# RTL8195AM register map
Vendor: Realtek; Series: Ameba IOT; File version: 1.2
SINGLE-CHIP 802.11b/g/n 1T1R WLAN SoC
CPU: CM3 r2p0, little endian, MPU, no FPU, vendor SysTick, 4 interrupt priority bits
Registers are 32-bit, read-write, reset 0x0 unless marked. A register's access mark holds for its fields unless they carry their own. Offsets are from the block's base; lines under a group give offsets from that group; [hi:lo] are bit positions; {n}, {i} and the like mark numbered series; 'fields as' and 'values as' point back to an identical list; <NAME> marks a mode.

## Memory map
0x40000000 SYSCON
0x40001000 GPIO
0x40002000 Timer
0x40003000 LOG_UART
0x40006000 SPI_flash_controller
0x40040000 UART_0
0x40042000 SSI0
0x40042400 SSI1
0x40042800 SSI2

## SYSCON
Base 0x40000000
0x00 PWR_CTRL 16-bit
0x02 ISO_CTRL 16-bit
0x08 FUNC_EN 4096-bit (reset mask 0xFFFFFFFF)
0x10 CLK_CTRL0 4096-bit (reset mask 0xFFFFFFFF)
0x14 CLK_CTRL1 4096-bit (reset mask 0xFFFFFFFF)
{0x20+4i} EFUSE_SYSCFG{i} 4096-bit (reset mask 0xFFFFFFFF) (i=0..7)
0x40 REGU_CTRL0 4096-bit (reset mask 0xFFFFFFFF)
0x48 SWR_CTRL0 4096-bit (reset mask 0xFFFFFFFF)
0x4C SWR_CTRL1 4096-bit (reset mask 0xFFFFFFFF)
0x60 XTAL_CTRL0 4096-bit (reset mask 0xFFFFFFFF)
0x64 XTAL_CTRL1 4096-bit (reset mask 0xFFFFFFFF)
{0x70+4i} SYSPLL_CTRL{i} 4096-bit (reset mask 0xFFFFFFFF) (i=0..2)
0x90 ANA_TIM_CTRL 4096-bit (reset mask 0xFFFFFFFF)
0x94 DSLP_TIM_CTRL 4096-bit (reset mask 0xFFFFFFFF)
0x98 DSLP_TIM_CAL_CTRL 4096-bit (reset mask 0xFFFFFFFF)
0xA0 DEBUG_CTRL 4096-bit (reset mask 0xFFFFFFFF)
0xA4 PINMUX_CTRL 4096-bit (reset mask 0xFFFFFFFF)
0xA8 GPIO_DSTBY_WAKE_CTRL0 4096-bit (reset mask 0xFFFFFFFF)
0xAC GPIO_DSTBY_WAKE_CTRL1 4096-bit (reset mask 0xFFFFFFFF)
0xBC DEBUG_REG 4096-bit (reset mask 0xFFFFFFFF)
0xE0 EEPROM_CTRL0 4096-bit (reset mask 0xFFFFFFFF)
0xE4 EEPROM_CTRL1 4096-bit (reset mask 0xFFFFFFFF)
0xE8 EFUSE_CTRL 4096-bit (reset mask 0xFFFFFFFF)
0xEC EFUSE_TEST 4096-bit (reset mask 0xFFFFFFFF)
{0xF0+4i} DSTBY_INFO{i} 4096-bit (reset mask 0xFFFFFFFF) (i=0..3)
0x100 SLP_WAKE_EVENT_MSK0 4096-bit (reset mask 0xFFFFFFFF)
0x104 SLP_WAKE_EVENT_MSK1 4096-bit (reset mask 0xFFFFFFFF)
0x108 SLP_WAKE_EVENT_STATUS0 4096-bit (reset mask 0xFFFFFFFF)
0x10C SLP_WAKE_EVENT_STATUS1 4096-bit (reset mask 0xFFFFFFFF)
0x110 SNF_WAKE_EVENT_MSK0 4096-bit (reset mask 0xFFFFFFFF)
0x114 SNF_WAKE_EVENT_STATUS 4096-bit (reset mask 0xFFFFFFFF)
0x118 PWRMGT_CTRL 4096-bit (reset mask 0xFFFFFFFF)
0x120 PWRMGT_OPTION 4096-bit (reset mask 0xFFFFFFFF)
0x124 PWRMGT_OPTION_EXT 4096-bit (reset mask 0xFFFFFFFF)
0x130 DSLP_WEVENT 4096-bit (reset mask 0xFFFFFFFF)
0x134 PERI_MONITOR 4096-bit (reset mask 0xFFFFFFFF)
{0x1F0+4i} SYSTEM_CFG{i} 4096-bit (reset mask 0xFFFFFFFF) (i=0..2)

## GPIO
Base 0x40001000
0x00 PORTA_DR — data register
0x04 PORTA_DDR — data direction
0x08 PORTA_CTRL — data source control
0x0C PORTB_DR — data register
0x10 PORTB_DDR — data direction
0x14 PORTB_CTRL — data source control
0x18 PORTC_DR — data register
0x1C PORTC_DDR — data direction
0x20 PORTC_CTRL — data source control
0x30 GPIO_INT_EN — Interrupt enable register
0x34 GPIO_INT_MASK — Interrupt mask
0x38 GPIO_INT_TYPE — Interrupt type(level/edge) register
0x3C GPIO_INT_POLARITY — Interrupt polarity(Active low/high) register
0x40 GPIO_INT_STATUS — Interrupt status
0x44 GPIO_INT_RAWSTATUS — Interrupt status without mask
0x48 GPIO_DEBOUNCE — Interrupt signal debounce
0x4C GPIO_PORTA_EOI — Clear interrupt
0x50 GPIO_EXT_PORTA — GPIO IN read or OUT read back
0x54 GPIO_EXT_PORTB — GPIO IN read or OUT read back
0x58 GPIO_EXT_PORTC — GPIO IN read or OUT read back
0x60 GPIO_INT_SYNC — Is level-sensitive interrupt being sync sith PCLK

## LOG_UART
Base 0x40003000
Same registers: UART_0 0x40040000
0x00 DLL
0x04 DLM — upper 8-bits of a 16-bit, Divisor Latch register RW, DLAB=1
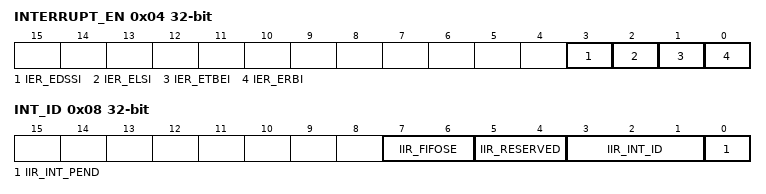
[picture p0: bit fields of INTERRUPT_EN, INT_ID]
0x04 INTERRUPT_EN (alternate view of DLM) — interrupt enable RW, DLAB=0
  [3] IER_EDSSI — Modem Status Interrupt
  [2] IER_ELSI — Receiver Line Status Interrupt
  [1] IER_ETBEI — Transmitter FIFO Empty Interrupt
  [0] IER_ERBI — Received Data Available Interrupt
0x08 INT_ID
  [7:6] IIR_FIFOSE — FIFOs Enabled 00=disabled 11=enabled
  [5:4] IIR_RESERVED
  [3:1] IIR_INT_ID
  [0] IIR_INT_PEND
0x08 FIFO_CTL
0x0C LINE_CTL
0x10 MODEM_CTL — Controls the interface with the MODEM or data set
0x14 LINE_STATUS ro — Provides status information concerning the data transfer.
0x18 MODEM_STATUS ro
0x1C SCRATCH_PAD
0x20 STS
0x24 REV_BUF ro — Receiver Buffer Register
0x24 TRAN_HOLD wo (alternate view of REV_BUF) — Transmitter Holding Register
0x28 MISC_CTL
0x3C DEBUG

## SPI_flash_controller
Base 0x40006000
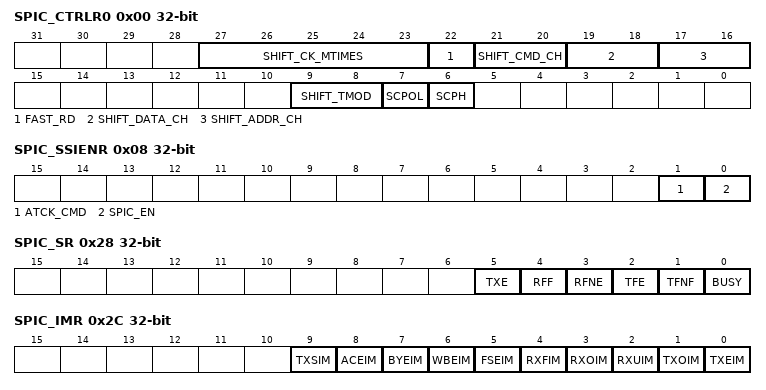
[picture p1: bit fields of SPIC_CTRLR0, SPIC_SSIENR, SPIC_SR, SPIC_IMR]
0x00 SPIC_CTRLR0
  [27:23] SHIFT_CK_MTIMES, [22] FAST_RD, [21:20] SHIFT_CMD_CH, [19:18] SHIFT_DATA_CH, [17:16] SHIFT_ADDR_CH, [9:8] SHIFT_TMOD, [7] SCPOL, [6] SCPH
0x04 SPIC_CTRLR1
  [11:0] SHIFT_NDF
0x08 SPIC_SSIENR
  [1] ATCK_CMD, [0] SPIC_EN
0x0C SPIC_MWCR
0x10 SPIC_SER
  [0] SER
0x14 SPIC_BAUDR
  [15:0] SHIFT_SCKDV
0x18 SPIC_TXFTLR
  [4:0] SHIFT_TFT
0x1C SPIC_RXFTLR
  [4:0] SHIFT_RFT
0x20 SPIC_TXFLR
  [5:0] SHIFT_TXFL
0x24 SPIC_RXFLR
  [5:0] SHIFT_RXFL
0x28 SPIC_SR
  [5] TXE, [4] RFF, [3] RFNE, [2] TFE, [1] TFNF, [0] BUSY
0x2C SPIC_IMR
  [9] TXSIM, [8] ACEIM, [7] BYEIM, [6] WBEIM, [5] FSEIM, [4] RXFIM, [3] RXOIM, [2] RXUIM, [1] TXOIM, [0] TXEIM
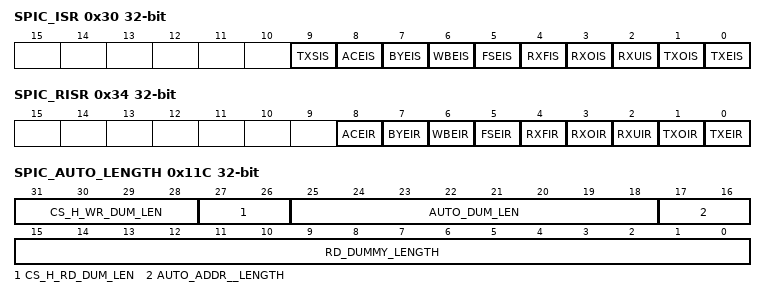
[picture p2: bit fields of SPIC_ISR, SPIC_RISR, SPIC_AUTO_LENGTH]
0x30 SPIC_ISR
  [9] TXSIS, [8] ACEIS, [7] BYEIS, [6] WBEIS, [5] FSEIS, [4] RXFIS, [3] RXOIS, [2] RXUIS, [1] TXOIS, [0] TXEIS
0x34 SPIC_RISR
  [8] ACEIR, [7] BYEIR, [6] WBEIR, [5] FSEIR, [4] RXFIR, [3] RXOIR, [2] RXUIR, [1] TXOIR, [0] TXEIR
0x38 SPIC_TXOICR
  [0] TXOICR
0x3C SPIC_RXOICR
  [0] RXOCIR
0x40 SPC_RXUICR
  [0] RXUICR
0x44 SPIC_MSTICR
  [0] MSTICR
0x48 SPIC_ICR
0x4C SPIC_DMACR
0x50 SPIC_DMATDLR0
0x54 SPIC_DMATDLR1
0x58 SPIC_IDR
0x5C SPIC_VERSION
{0x60+4i} SPIC_DR{i} (i=0..31)
0xE0 SPIC_READ_FAST_SINGLE
0xE4 SPIC_READ_DUAL_DATA
0xE8 SPIC_READ_DUAL_ADDR_DATA
0xEC SPIC_READ_QUAD_DATA
0xF0 SPIC_READ_QUAD_ADDR_DATA
0xF4 SPIC_WRITE_SIGNLE
0xF8 SPIC_WRITE_DUAL_DATA
0xFC SPIC_WRITE_DUAL_ADDR_DATA
0x100 SPIC_WRITE_QUAD_DATA
0x104 SPIC_WRITE_QUAD_ADDR_DATA
0x108 SPIC_WRITE_ENABLE
0x10C SPIC_READ_STATUS
0x110 SPIC_CTRLR2
0x114 SPIC_FBAUDR
  [11:0] FSCKDV
0x118 SPIC_ADDR_LENGTH
  [1:0] ADDR_PHASE_LENGTH
0x11C SPIC_AUTO_LENGTH
  [31:28] CS_H_WR_DUM_LEN, [27:26] CS_H_RD_DUM_LEN, [25:18] AUTO_DUM_LEN, [17:16] AUTO_ADDR__LENGTH, [15:0] RD_DUMMY_LENGTH
0x120 SPIC_VALID_CMD
0x124 SPIC_FLASE_SIZE
  [3:0] FLASE_SIZE
0x128 SPIC_FLUSH_FIFO

## SSI0
Base 0x40042000
Same registers: SSI1 0x40042400, SSI2 0x40042800
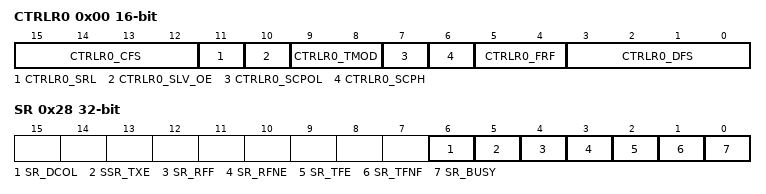
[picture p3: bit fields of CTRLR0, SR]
0x00 CTRLR0 16-bit
  [15:12] CTRLR0_CFS, [11] CTRLR0_SRL, [10] CTRLR0_SLV_OE, [9:8] CTRLR0_TMOD, [7] CTRLR0_SCPOL, [6] CTRLR0_SCPH, [5:4] CTRLR0_FRF, [3:0] CTRLR0_DFS
0x04 CTRLR1 16-bit
0x08 SSIENR
0x0C MWCR
0x10 SER
0x14 BAUDR 16-bit
0x18 TXFTLR
0x1C RXFTLR
0x20 TXFLR ro
0x24 RXFLR
0x28 SR ro
  [6] SR_DCOL, [5] SSR_TXE, [4] SR_RFF, [3] SR_RFNE, [2] SR_TFE, [1] SR_TFNF, [0] SR_BUSY
0x2C IMR
0x30 ISR
0x34 RISR
0x38 TXOICR
0x3C RXOICR
0x40 RXUICR
0x44 MSTICR
0x48 ICR
0x4C DMACR
0x50 DMATDLR
0x54 DMARDLR
0x58 IDR
0x5C COMP_VERSION
{0x60+2i} DR[{i}] (i=0..69) 16-bit
0xF0 RX_SAMPLE_DLY 8-bit

## Licence text in the file
ARM Limited (ARM) is supplying this software for use with Cortex-M processor based microcontroller, but can be equally used for other suitable processor architectures. This file can be freely distributed. Modifications to this file shall be clearly marked. . THIS SOFTWARE IS PROVIDED "AS IS". NO WARRANTIES, WHETHER EXPRESS, IMPLIED. OR STATUTORY, INCLUDING, BUT NOT LIMITED TO, IMPLIED WARRANTIES OF. MERCHANTABILITY AND FITNESS FOR A PARTICULAR PURPOSE APPLY TO THIS SOFTWARE. ARM SHALL NOT, IN ANY CIRCUMSTANCES, BE LIABLE FOR SPECIAL, INCIDENTAL, OR. CONSEQUENTIAL DAMAGES, FOR ANY REASON WHATSOEVER.

## Notices in the file
Copyright (C) 2012-2014 ARM Limited. All rights reserved. Purpose: System
Viewer Description (SVD) Example (Schema Version 1.1) This is a description
of a none-existent and incomplete device for demonstration purposes only.
Redistribution and use in source and binary forms, with or without modification,
are permitted provided that the following conditions are met: - Redistributions
of source code must retain the above copyright notice, this list of conditions
and the following disclaimer. - Redistributions in binary form must reproduce
the above copyright notice, this list of conditions and the following disclaimer
in the documentation and/or other materials provided with the distribution.
- Neither the name of ARM nor the names of its contributors may be used to
endorse or promote products derived from this software without specific prior
written permission. THIS SOFTWARE IS PROVIDED BY THE COPYRIGHT HOLDERS AND
CONTRIBUTORS "AS IS" AND ANY EXPRESS OR IMPLIED WARRANTIES, INCLUDING, BUT
NOT LIMITED TO, THE IMPLIED WARRANTIES OF MERCHANTABILITY AND FITNESS FOR
A PARTICULAR PURPOSE ARE DISCLAIMED. IN NO EVENT SHALL COPYRIGHT HOLDERS
AND CONTRIBUTORS BE LIABLE FOR ANY DIRECT, INDIRECT, INCIDENTAL, SPECIAL,
EXEMPLARY, OR CONSEQUENTIAL DAMAGES (INCLUDING, BUT NOT LIMITED TO, PROCUREMENT
OF SUBSTITUTE GOODS OR SERVICES; LOSS OF USE, DATA, OR PROFITS; OR BUSINESS
INTERRUPTION) HOWEVER CAUSED AND ON ANY THEORY OF LIABILITY, WHETHER IN CONTRACT,
STRICT LIABILITY, OR TORT (INCLUDING NEGLIGENCE OR OTHERWISE) ARISING IN
ANY WAY OUT OF THE USE OF THIS SOFTWARE, EVEN IF ADVISED OF THE POSSIBILITY
OF SUCH DAMAGE.
